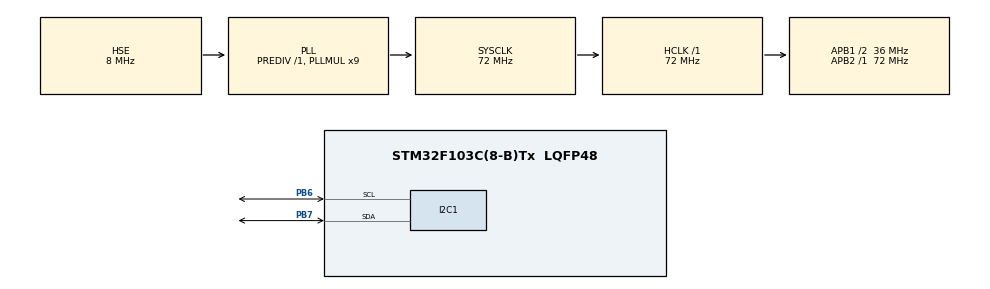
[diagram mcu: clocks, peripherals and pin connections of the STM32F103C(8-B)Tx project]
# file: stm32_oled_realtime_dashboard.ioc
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Mcu.Family=STM32F1
Mcu.Name=STM32F103C(8-B)Tx
Mcu.Package=LQFP48
NVIC.PriorityGroup=NVIC_PRIORITYGROUP_4
NVIC.TIM2_IRQn=true\:0\:0\:false\:false\:true\:true\:true\:true
PB6.Mode=I2C
PB6.Signal=I2C1_SCL
PB7.Mode=I2C
PB7.Signal=I2C1_SDA
PD0-OSC_IN.Mode=HSE-External-Oscillator
PD0-OSC_IN.Signal=RCC_OSC_IN
PD1-OSC_OUT.Mode=HSE-External-Oscillator
PD1-OSC_OUT.Signal=RCC_OSC_OUT
ProjectManager.HeapSize=0x200
ProjectManager.StackSize=0x400
ProjectManager.TargetToolchain=MDK-ARM V5.32
RCC.AHBFreq_Value=72000000
RCC.APB1CLKDivider=RCC_HCLK_DIV2
RCC.APB1Freq_Value=36000000
RCC.APB1TimFreq_Value=72000000
RCC.APB2Freq_Value=72000000
RCC.APB2TimFreq_Value=72000000
RCC.HCLKFreq_Value=72000000
RCC.PLLMUL=RCC_PLL_MUL9
RCC.PLLSourceVirtual=RCC_PLLSOURCE_HSE
RCC.SYSCLKFreq_VALUE=72000000
RCC.SYSCLKSource=RCC_SYSCLKSOURCE_PLLCLK
RCC.USBFreq_Value=72000000
TIM2.AutoReloadPreload=TIM_AUTORELOAD_PRELOAD_ENABLE
TIM2.Period=10000
TIM2.Prescaler=7200-1
VP_SYS_VS_ND.Mode=No_Debug
VP_TIM2_VS_ClockSourceINT.Mode=Internal
board=custom

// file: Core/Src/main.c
/* USER CODE BEGIN Header */
/**
  ******************************************************************************
  * @file           : main.c
  * @brief          : Main program body
  ******************************************************************************
  * @attention
  *
  * Copyright (c) 2025 STMicroelectronics.
  * All rights reserved.
  *
  * This software is licensed under terms that can be found in the LICENSE file
  * in the root directory of this software component.
  * If no LICENSE file comes with this software, it is provided AS-IS.
  *
  ******************************************************************************
  */
/* USER CODE END Header */
#include "main.h"
#include "i2c.h"
#include "tim.h"
#include "gpio.h"
#include "MPU6050.h"
#include "ssd1306.h"
#include <math.h>

/* USER CODE BEGIN PV */
MPU6050_t MPU6050;          // 存加速度
char oled_buf[32];          // 临时字符串
/* USER CODE END PV */

void SystemClock_Config(void);

int main(void)
{

  /* MCU Configuration--------------------------------------------------------*/

  /* Reset of all peripherals, Initializes the Flash interface and the Systick. */
  HAL_Init();

  /* Configure the system clock */
  SystemClock_Config();

  /* Initialize all configured peripherals */
  MX_GPIO_Init();
  MX_I2C1_Init();
  MX_TIM2_Init();
  /* USER CODE BEGIN 2 */
	if (MPU6050_Init(&hi2c1) !=0 ) {
		Error_Handler();// 失败就停
	}
	if (ssd1306_Init(&hi2c1) != 0) {
    Error_Handler();          // 初始化失败就停
	}

	HAL_TIM_Base_Start_IT(&htim2);

  /* USER CODE END 2 */

  /* Infinite loop */
  while (1)
  {

  }
}

void HAL_TIM_PeriodElapsedCallback(TIM_HandleTypeDef *htim)
{
		if (htim->Instance == TIM2)        // 只处理 TIM2
		{
				/* 这里写 1 秒要做的事情 */
//				/* 采样 */
//			MPU6050_Read_Accel(&hi2c1, &MPU6050);
//
//			/* 组字符串 */
//			sprintf(oled_buf, "Ax:%.2fg", MPU6050.Ax);
//			ssd1306_SetCursor(0, 0);
//			ssd1306_WriteString(oled_buf, Font_7x10, White);

//			sprintf(oled_buf, "Ay:%.2fg", MPU6050.Ay);
//			ssd1306_SetCursor(0, 10);
//			ssd1306_WriteString(oled_buf, Font_7x10, White);

//			sprintf(oled_buf, "Az:%.2fg", MPU6050.Az);
//			ssd1306_SetCursor(0, 20);
//			ssd1306_WriteString(oled_buf, Font_7x10, White);

//			/* 一次性刷新到屏幕 */
//			ssd1306_UpdateScreen(&hi2c1);
		static double buf[5] = {0};              // 存 10 次角度
		static uint8_t idx = 0;                   // 循环指针

		MPU6050_Read_All(&hi2c1, &MPU6050);

		double pitch = atan2(-MPU6050.Ax, MPU6050.Az) * 57.3;
    buf[idx] = pitch;                         // 存新角度
		idx = (idx + 1) % 10;                     // 循环存
		double avg = 0;
		for (uint8_t i = 0; i < 5; i++) avg += buf[i];
		avg /= 5;                              // 取平均
		int len = (int)fabs(avg) * 2;
		ssd1306_Fill(Black);
		for(int i=0;i<len;i++)
		{
			ssd1306_DrawPixel(64-i, 40, White);
		}ssd1306_UpdateScreen(&hi2c1);

//		if(avg<0)
//		{
//			int len = (int)fabs(avg) * 2;
//			ssd1306_Fill(Black);
//			for(int i=0;i<len;i++)
//			{
//				ssd1306_DrawPixel(64-i, 40, White);
//			}ssd1306_UpdateScreen(&hi2c1);
//		}
//		else
//		{
//			int len = (int)fabs(avg) * 2;
//			ssd1306_Fill(Black);
//			for(int i=0;i<len;i++)
//			{
//				ssd1306_DrawPixel(64+i, 40, White);
//			}ssd1306_UpdateScreen(&hi2c1);
//		}

		}
}
void SystemClock_Config(void)
{
  RCC_OscInitTypeDef RCC_OscInitStruct = {0};
  RCC_ClkInitTypeDef RCC_ClkInitStruct = {0};

  /** Initializes the RCC Oscillators according to the specified parameters
  * in the RCC_OscInitTypeDef structure.
  */
  RCC_OscInitStruct.OscillatorType = RCC_OSCILLATORTYPE_HSE;
  RCC_OscInitStruct.HSEState = RCC_HSE_ON;
  RCC_OscInitStruct.HSEPredivValue = RCC_HSE_PREDIV_DIV1;
  RCC_OscInitStruct.HSIState = RCC_HSI_ON;
  RCC_OscInitStruct.PLL.PLLState = RCC_PLL_ON;
  RCC_OscInitStruct.PLL.PLLSource = RCC_PLLSOURCE_HSE;
  RCC_OscInitStruct.PLL.PLLMUL = RCC_PLL_MUL9;
  if (HAL_RCC_OscConfig(&RCC_OscInitStruct) != HAL_OK)
  {
    Error_Handler();
  }

  /** Initializes the CPU, AHB and APB buses clocks
  */
  RCC_ClkInitStruct.ClockType = RCC_CLOCKTYPE_HCLK|RCC_CLOCKTYPE_SYSCLK
                              |RCC_CLOCKTYPE_PCLK1|RCC_CLOCKTYPE_PCLK2;
  RCC_ClkInitStruct.SYSCLKSource = RCC_SYSCLKSOURCE_PLLCLK;
  RCC_ClkInitStruct.AHBCLKDivider = RCC_SYSCLK_DIV1;
  RCC_ClkInitStruct.APB1CLKDivider = RCC_HCLK_DIV2;
  RCC_ClkInitStruct.APB2CLKDivider = RCC_HCLK_DIV1;

  if (HAL_RCC_ClockConfig(&RCC_ClkInitStruct, FLASH_LATENCY_2) != HAL_OK)
  {
    Error_Handler();
  }
}

void Error_Handler(void)
{
  __disable_irq();
  while (1)
  {
  }
}
